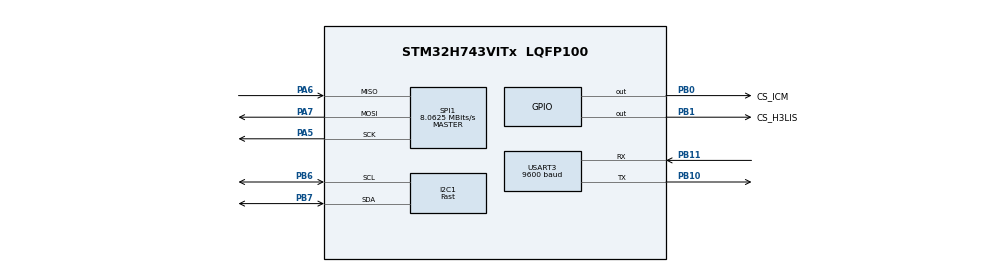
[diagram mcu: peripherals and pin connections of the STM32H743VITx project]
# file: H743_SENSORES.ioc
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CORTEX_M7.default_mode_Activation=1
I2C1.I2C_Speed_Mode=I2C_Fast
I2C1.Timing=0x00602173
Mcu.Family=STM32H7
Mcu.Name=STM32H743VITx
Mcu.Package=LQFP100
NVIC.PriorityGroup=NVIC_PRIORITYGROUP_4
PA13\ (JTMS/SWDIO).Mode=Serial_Wire
PA13\ (JTMS/SWDIO).Signal=DEBUG_JTMS-SWDIO
PA14\ (JTCK/SWCLK).Mode=Serial_Wire
PA14\ (JTCK/SWCLK).Signal=DEBUG_JTCK-SWCLK
PA5.Mode=Full_Duplex_Master
PA5.Signal=SPI1_SCK
PA6.Mode=Full_Duplex_Master
PA6.Signal=SPI1_MISO
PA7.Mode=Full_Duplex_Master
PA7.Signal=SPI1_MOSI
PB0.GPIO_Label=CS_ICM
PB0.PinState=GPIO_PIN_SET
PB0.Signal=GPIO_Output
PB1.GPIO_Label=CS_H3LIS
PB1.PinState=GPIO_PIN_SET
PB1.Signal=GPIO_Output
PB10.Mode=Asynchronous
PB10.Signal=USART3_TX
PB11.Mode=Asynchronous
PB11.Signal=USART3_RX
PB6.Mode=I2C
PB6.Signal=I2C1_SCL
PB7.Mode=I2C
PB7.Signal=I2C1_SDA
ProjectManager.HeapSize=0x200
ProjectManager.StackSize=0x400
ProjectManager.TargetToolchain=STM32CubeIDE
RCC.ADCFreq_Value=129000000
RCC.APB1Freq_Value=64000000
RCC.APB2Freq_Value=64000000
RCC.APB3Freq_Value=64000000
RCC.APB4Freq_Value=64000000
RCC.CortexFreq_Value=64000000
RCC.HCLKFreq_Value=64000000
RCC.SYSCLKFreq_VALUE=64000000
RCC.USBFreq_Value=129000000
SPI1.BaudRatePrescaler=SPI_BAUDRATEPRESCALER_16
SPI1.CalculateBaudRate=8.0625 MBits/s
SPI1.DataSize=SPI_DATASIZE_8BIT
SPI1.Direction=SPI_DIRECTION_2LINES
SPI1.Mode=SPI_MODE_MASTER
SPI1.VirtualType=VM_MASTER
USART3.BaudRate=9600
USART3.VirtualMode-Asynchronous=VM_ASYNC
VP_MEMORYMAP_VS_MEMORYMAP.Mode=CurAppReg
board=custom

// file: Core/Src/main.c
/* USER CODE BEGIN Header */
/**
  ******************************************************************************
  * @file           : main.c
  * @brief          : Main program body
  ******************************************************************************
  * @attention
  *
  * Copyright (c) 2026 STMicroelectronics.
  * All rights reserved.
  *
  * This software is licensed under terms that can be found in the LICENSE file
  * in the root directory of this software component.
  * If no LICENSE file comes with this software, it is provided AS-IS.
  *
  ******************************************************************************
  */
/* USER CODE END Header */
#include "main.h"
#include "i2c.h"
#include "spi.h"
#include "usart.h"
#include "gpio.h"
/*ahora los sensores*/
#include "icm42688.h"
#include "h3lis331.h"
#include "ms5607.h"
#include "max_m10s.h"

/* USER CODE BEGIN PV */

uint8_t whoAmI = 0;

int16_t accelX = 0;
int16_t accelY = 0;
int16_t accelZ = 0;

int16_t gyroX = 0;
int16_t gyroY = 0;
int16_t gyroZ = 0;

uint8_t h3lisWhoAmI = 0;

int16_t h3lisAccelX = 0;
int16_t h3lisAccelY = 0;
int16_t h3lisAccelZ = 0;

uint32_t pressure = 0;
int32_t temperature = 0;

/* USER CODE END PV */

void SystemClock_Config(void);
static void MPU_Config(void);

int main(void)
{

  /* MPU Configuration--------------------------------------------------------*/
  MPU_Config();

  /* MCU Configuration--------------------------------------------------------*/

  /* Reset of all peripherals, Initializes the Flash interface and the Systick. */
  HAL_Init();

  /* Configure the system clock */
  SystemClock_Config();

  /* Initialize all configured peripherals */
  MX_GPIO_Init();
  MX_I2C1_Init();
  MX_SPI1_Init();
  MX_USART3_UART_Init();

  /* USER CODE BEGIN 2 */

  /* Los sensores están integrados mediante sus respectivos drivers.
   * La comunicación física se comprobará cuando estén conectados.
   */

  /* USER CODE END 2 */

  /* Infinite loop */
  while (1)
  {

    /* USER CODE BEGIN 3 */

    HAL_Delay(10);

    /* USER CODE END 3 */
  }

}
void SystemClock_Config(void)
{
  RCC_OscInitTypeDef RCC_OscInitStruct = {0};
  RCC_ClkInitTypeDef RCC_ClkInitStruct = {0};

  /** Supply configuration update enable
  */
  HAL_PWREx_ConfigSupply(PWR_LDO_SUPPLY);

  /** Configure the main internal regulator output voltage
  */
  __HAL_PWR_VOLTAGESCALING_CONFIG(PWR_REGULATOR_VOLTAGE_SCALE3);

  while(!__HAL_PWR_GET_FLAG(PWR_FLAG_VOSRDY)) {}

  /** Initializes the RCC Oscillators according to the specified parameters
  * in the RCC_OscInitTypeDef structure.
  */
  RCC_OscInitStruct.OscillatorType = RCC_OSCILLATORTYPE_HSI;
  RCC_OscInitStruct.HSIState = RCC_HSI_DIV1;
  RCC_OscInitStruct.HSICalibrationValue = RCC_HSICALIBRATION_DEFAULT;
  RCC_OscInitStruct.PLL.PLLState = RCC_PLL_ON;
  RCC_OscInitStruct.PLL.PLLSource = RCC_PLLSOURCE_HSI;
  RCC_OscInitStruct.PLL.PLLM = 32;
  RCC_OscInitStruct.PLL.PLLN = 129;
  RCC_OscInitStruct.PLL.PLLP = 2;
  RCC_OscInitStruct.PLL.PLLQ = 2;
  RCC_OscInitStruct.PLL.PLLR = 2;
  RCC_OscInitStruct.PLL.PLLRGE = RCC_PLL1VCIRANGE_1;
  RCC_OscInitStruct.PLL.PLLVCOSEL = RCC_PLL1VCOWIDE;
  RCC_OscInitStruct.PLL.PLLFRACN = 0;
  if (HAL_RCC_OscConfig(&RCC_OscInitStruct) != HAL_OK)
  {
    Error_Handler();
  }

  /** Initializes the CPU, AHB and APB buses clocks
  */
  RCC_ClkInitStruct.ClockType = RCC_CLOCKTYPE_HCLK|RCC_CLOCKTYPE_SYSCLK
                              |RCC_CLOCKTYPE_PCLK1|RCC_CLOCKTYPE_PCLK2
                              |RCC_CLOCKTYPE_D3PCLK1|RCC_CLOCKTYPE_D1PCLK1;
  RCC_ClkInitStruct.SYSCLKSource = RCC_SYSCLKSOURCE_HSI;
  RCC_ClkInitStruct.SYSCLKDivider = RCC_SYSCLK_DIV1;
  RCC_ClkInitStruct.AHBCLKDivider = RCC_HCLK_DIV1;
  RCC_ClkInitStruct.APB3CLKDivider = RCC_APB3_DIV1;
  RCC_ClkInitStruct.APB1CLKDivider = RCC_APB1_DIV1;
  RCC_ClkInitStruct.APB2CLKDivider = RCC_APB2_DIV1;
  RCC_ClkInitStruct.APB4CLKDivider = RCC_APB4_DIV1;

  if (HAL_RCC_ClockConfig(&RCC_ClkInitStruct, FLASH_LATENCY_1) != HAL_OK)
  {
    Error_Handler();
  }
}

 /* MPU Configuration */

void MPU_Config(void)
{
  MPU_Region_InitTypeDef MPU_InitStruct = {0};

  /* Disables the MPU */
  HAL_MPU_Disable();

  /** Initializes and configures the Region and the memory to be protected
  */
  MPU_InitStruct.Enable = MPU_REGION_ENABLE;
  MPU_InitStruct.Number = MPU_REGION_NUMBER0;
  MPU_InitStruct.BaseAddress = 0x0;
  MPU_InitStruct.Size = MPU_REGION_SIZE_4GB;
  MPU_InitStruct.SubRegionDisable = 0x87;
  MPU_InitStruct.TypeExtField = MPU_TEX_LEVEL0;
  MPU_InitStruct.AccessPermission = MPU_REGION_NO_ACCESS;
  MPU_InitStruct.DisableExec = MPU_INSTRUCTION_ACCESS_DISABLE;
  MPU_InitStruct.IsShareable = MPU_ACCESS_SHAREABLE;
  MPU_InitStruct.IsCacheable = MPU_ACCESS_NOT_CACHEABLE;
  MPU_InitStruct.IsBufferable = MPU_ACCESS_NOT_BUFFERABLE;

  HAL_MPU_ConfigRegion(&MPU_InitStruct);
  /* Enables the MPU */
  HAL_MPU_Enable(MPU_PRIVILEGED_DEFAULT);

}

void Error_Handler(void)
{
  __disable_irq();
  while (1)
  {
  }
}
